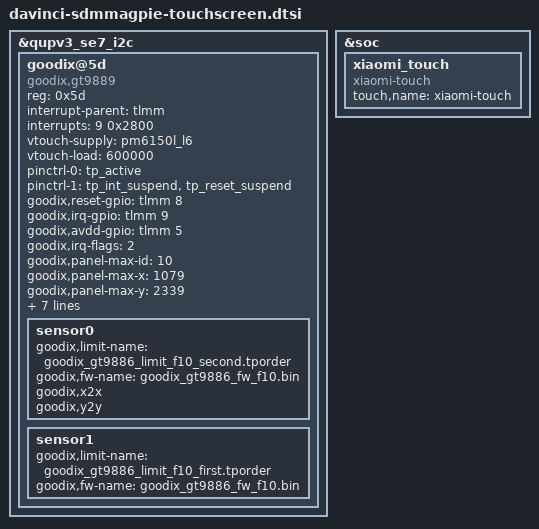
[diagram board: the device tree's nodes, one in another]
/*
 * Copyright (C) 2020 The LineageOS Project
 *
 * this file is for attribution only of davinci
 * And public attribution of Xiaomi platforms (like F10 and so)
 */

&qupv3_se7_i2c{
    status = "ok";
    goodix@5d {
        compatible = "goodix,gt9889";
        reg = <0x5d>;
        status = "ok";
        interrupt-parent = <&tlmm>;
        interrupts = <9 0x2800>;
        vtouch-supply = <&pm6150l_l6>;//3.3v
        vtouch-load = <600000>;
        pinctrl-names = "pmx_ts_active","pmx_ts_suspend";
        pinctrl-0 = <&tp_active>;
        pinctrl-1 = <&tp_int_suspend &tp_reset_suspend>;
        goodix,reset-gpio = <&tlmm 8 0x0>;
        goodix,irq-gpio = <&tlmm 9 0x2800>;         /* 3v3 */
        goodix,avdd-gpio = <&tlmm 5 0x0>;           /* 1v8 */
        goodix,irq-flags = <2>; /* 1:trigger rising, 2:trigger falling;*/
        goodix,panel-max-id = <10>;
        goodix,panel-max-x = <1079>;
        goodix,panel-max-y = <2339>;
        goodix,panel-max-w = <127>;
        goodix,panel-max-p = <127>;
        goodix,panel-max-fod = <127>;
        goodix,power-on-delay-us = <300000>; /*300ms*/
        goodix,power-off-delay-us = <5000>;
        goodix,cfg-name = "goodix_gt9886_cfg_f10.bin";
        normal-cfg = [
                ];
        sensor0 {
                goodix,limit-name = "goodix_gt9886_limit_f10_second.tporder";
                goodix,fw-name = "goodix_gt9886_fw_f10.bin";
                goodix,x2x;
                goodix,y2y;
        };
        sensor1 {
                goodix,limit-name = "goodix_gt9886_limit_f10_first.tporder";
                goodix,fw-name = "goodix_gt9886_fw_f10.bin";
        };
    };
};

&soc {
    xiaomi_touch {
        compatible = "xiaomi-touch";
        status = "ok";
        touch,name = "xiaomi-touch";
    };
};
